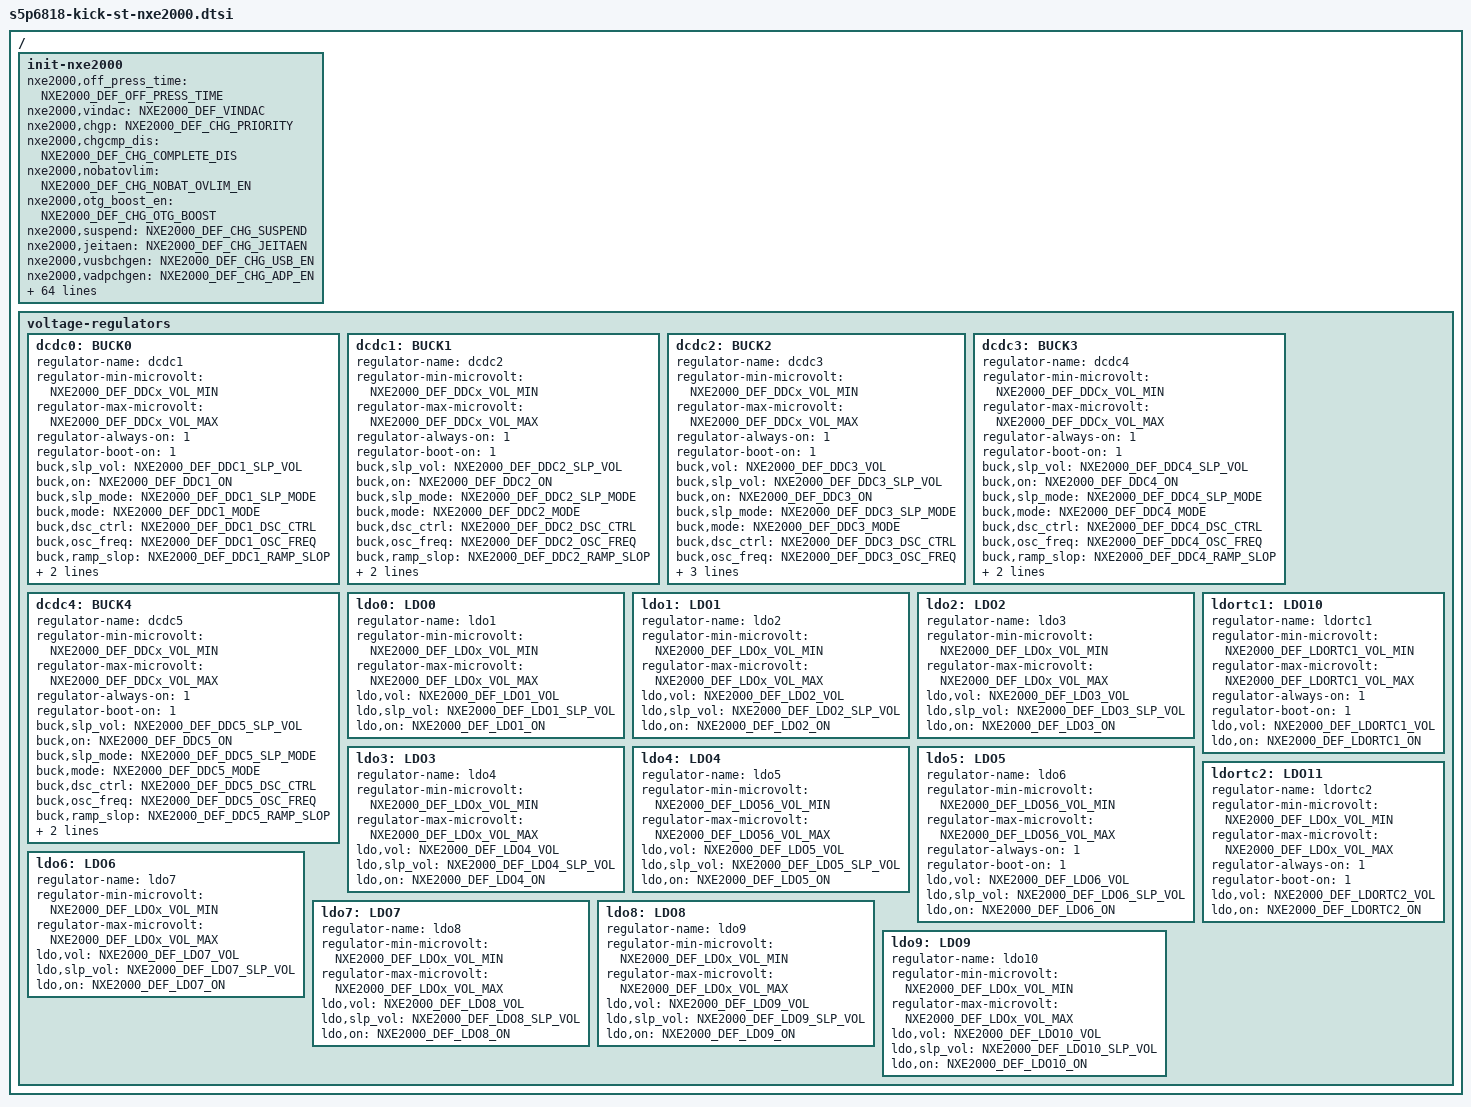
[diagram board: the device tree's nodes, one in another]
/*
 * (C) Copyright 2017 Nexell
 * Jongshin, Park <pjsin865@nexell.co.kr>
 *
 * SPDX-License-Identifier:      GPL-2.0+
 */

/*
 *	Config Value
 */

/* Off Press time Value = 0:0, 1:1, 2:2, 3:4, 4:6, 5:8, 6:10, 7:12 sec */
#define	NXE2000_DEF_OFF_PRESS_TIME 5

/* VINDAC Value = 0:2.6, 1:2.7, 2:2.8, 3:2.9, OTP = 2 */
#define	NXE2000_DEF_VINDAC 0

/* Limit Current Value(uA) */
#define NXE2000_DEF_LIMIT_ADP_AMP 2500000 /* MAX = 2.5A */
#define NXE2000_DEF_LIMIT_USB_AMP 1500000 /* MAX = 1.5A */
#define NXE2000_DEF_LIMIT_USBDATA_AMP 500000 /* MAX = 1.5A */

/* Charge Current Value(uA) */
#define NXE2000_DEF_CHG_ADP_AMP 1500000 /* MAX = 1.8A */
#define NXE2000_DEF_CHG_USB_AMP 1500000 /* MAX = 1.8A */
#define CHARGER_CURRENT_COMPLETE 3 /* (n + 1) x 50mA */

/* Battery Votage Value(uV) */
#define	NXE2000_DEF_CUTOFF_VOL 3300000
#define	NXE2000_DEF_LOWBAT_BATTERY_VOL 3500000
#define	NXE2000_DEF_LOWBAT_USB_PC_VOL 3600000
#define	NXE2000_DEF_LOWBAT_USB_ADP_VOL 3660000
#define	NXE2000_DEF_LOWBAT_ADP_VOL 3660000

/* DCDC Enable Value = 0: Off, 1: On, OTP = On */
#define	NXE2000_DEF_DDC1_ON 1
#define	NXE2000_DEF_DDC2_ON 1
#define	NXE2000_DEF_DDC3_ON 1
#define	NXE2000_DEF_DDC4_ON 1
#define	NXE2000_DEF_DDC5_ON 1

/* DCDC Voltage Value(uV) = 0: 0.60 ~ 3.5V, Step 12.5 mV */
#define	NXE2000_DEF_DDC1_VOL 1250000 /* OTP = 1.3V */
#define	NXE2000_DEF_DDC2_VOL 1200000 /* OTP = 1.2V */
#define	NXE2000_DEF_DDC3_VOL 3300000 /* OTP = 3.3V */
#define	NXE2000_DEF_DDC4_VOL 1500000 /* OTP = 1.5V */
#define	NXE2000_DEF_DDC5_VOL 1500000 /* OTP = 1.5V */

/* DCDC Sleep Voltage Value(uV) = 0: 0.60 ~ 3.5V, Step 12.5 mV */
#define	NXE2000_DEF_DDC1_SLP_VOL 1250000 /* OTP = 1.3V */
#define	NXE2000_DEF_DDC2_SLP_VOL 1200000 /* OTP = 1.2V */
#define	NXE2000_DEF_DDC3_SLP_VOL 3300000 /* OTP = 3.3V */
#define	NXE2000_DEF_DDC4_SLP_VOL 1500000 /* OTP = 1.5V */
#define	NXE2000_DEF_DDC5_SLP_VOL 1500000 /* OTP = 1.5V */

/* LDO Enable Value = 0: Off, 1: On */
#define	NXE2000_DEF_LDO1_ON 0
#define	NXE2000_DEF_LDO2_ON 0
#define	NXE2000_DEF_LDO3_ON 1
#define	NXE2000_DEF_LDO4_ON 0
#define	NXE2000_DEF_LDO5_ON 1
#define	NXE2000_DEF_LDO6_ON 1
#define	NXE2000_DEF_LDO7_ON 1
#define	NXE2000_DEF_LDO8_ON 0
#define	NXE2000_DEF_LDO9_ON 0
#define	NXE2000_DEF_LDO10_ON 1
#define	NXE2000_DEF_LDORTC1_ON 1
#define	NXE2000_DEF_LDORTC2_ON 1

/* LDO1~4 Voltage Value(uV) = 0: 0.90 ~ 3.5V, Step = 25mV */
/* LDO5~6 Voltage Value(uV) = 0: 0.60 ~ 3.5V, Step = 25mV */
/* LDO7~10 Voltage Value(uV) = 0: 0.90 ~ 3.5V, Step = 25mV */
#define	NXE2000_DEF_LDO1_VOL 2800000 /* OTP = 3.30V */
#define	NXE2000_DEF_LDO2_VOL 1800000 /* OTP = 1.80V */
#define	NXE2000_DEF_LDO3_VOL 1800000 /* OTP = 1.80V */
#define	NXE2000_DEF_LDO4_VOL 1800000 /* OTP = 1.80V */
#define	NXE2000_DEF_LDO5_VOL 1200000 /* OTP = 2.80V */
#define	NXE2000_DEF_LDO6_VOL 3300000 /* OTP = 3.30V */
#define	NXE2000_DEF_LDO7_VOL 2800000 /* OTP = 2.80V */
#define	NXE2000_DEF_LDO8_VOL 3300000 /* OTP = 3.30V */
#define	NXE2000_DEF_LDO9_VOL 3300000 /* OTP = 3.30V */
#define	NXE2000_DEF_LDO10_VOL 1000000 /* OTP = 1.20V */
#define	NXE2000_DEF_LDORTC1_VOL 1800000 /* OTP = 1.80V */
#define	NXE2000_DEF_LDORTC2_VOL 1000000 /* OTP = 1.00V */

/* LDO1~4 Sleep Voltage Value(uV) = 0: 0.90 ~ 3.5V, Step = 25mV */
/* LDO5~6 Sleep Voltage Value(uV) = 0: 0.60 ~ 3.5V, Step = 25mV */
/* LDO7~10 Sleep Voltage Value(uV) = 0: 0.90 ~ 3.5V, Step = 25mV */
#define	NXE2000_DEF_LDO1_SLP_VOL 2800000 /* OTP = 3.30V */
#define	NXE2000_DEF_LDO2_SLP_VOL 1800000 /* OTP = 1.80V */
#define	NXE2000_DEF_LDO3_SLP_VOL 1800000 /* OTP = 1.80V */
#define	NXE2000_DEF_LDO4_SLP_VOL 1800000 /* OTP = 1.80V */
#define	NXE2000_DEF_LDO5_SLP_VOL 1200000 /* OTP = 2.80V */
#define	NXE2000_DEF_LDO6_SLP_VOL 3300000 /* OTP = 3.30V */
#define	NXE2000_DEF_LDO7_SLP_VOL 2800000 /* OTP = 2.80V */
#define	NXE2000_DEF_LDO8_SLP_VOL 3300000 /* OTP = 3.30V */
#define	NXE2000_DEF_LDO9_SLP_VOL 3300000 /* OTP = 3.30V */
#define	NXE2000_DEF_LDO10_SLP_VOL 1000000 /* OTP = 1.20V */

/* DCDC and LDO Min/Max/Step Value */
#define	NXE2000_DEF_DDCx_VOL_STEP 12500
#define	NXE2000_DEF_LDOx_VOL_STEP 25000
#define	NXE2000_DEF_DDCx_VOL_MIN 600000
#define	NXE2000_DEF_DDCx_VOL_MAX 3500000
#define	NXE2000_DEF_LDOx_VOL_MIN 900000
#define	NXE2000_DEF_LDOx_VOL_MAX 3500000
#define	NXE2000_DEF_LDO56_VOL_MIN 600000
#define	NXE2000_DEF_LDO56_VOL_MAX 3500000
#define	NXE2000_DEF_LDORTC1_VOL_MIN 1700000
#define	NXE2000_DEF_LDORTC1_VOL_MAX 3500000

/* DCDC Mode Value = 0:AUTO(OTP), 1:PWM, 2:PSM, 3:AUTO */
#define	NXE2000_DEF_DDC1_MODE 0
#define	NXE2000_DEF_DDC2_MODE 0
#define	NXE2000_DEF_DDC3_MODE 0
#define	NXE2000_DEF_DDC4_MODE 0
#define	NXE2000_DEF_DDC5_MODE 0

/* DCDC Sleep Mode Value = 0:AUTO(OTP), 1:PWM, 2:PSM, 3:AUTO */
#define	NXE2000_DEF_DDC1_SLP_MODE 0
#define	NXE2000_DEF_DDC2_SLP_MODE 0
#define	NXE2000_DEF_DDC3_SLP_MODE 0
#define	NXE2000_DEF_DDC4_SLP_MODE 0
#define	NXE2000_DEF_DDC5_SLP_MODE 0

/* DCDC DSC Control Value = 0: Off, 1: On(OTP) */
#define	NXE2000_DEF_DDC1_DSC_CTRL 1
#define	NXE2000_DEF_DDC2_DSC_CTRL 1
#define	NXE2000_DEF_DDC3_DSC_CTRL 1
#define	NXE2000_DEF_DDC4_DSC_CTRL 1
#define	NXE2000_DEF_DDC5_DSC_CTRL 1

/* DCDC OSC FREQ Value(MHz) = 0: 1.5, 1: x, 2: 3.0, 3: x, OTP = 1.5MHz */
#define	NXE2000_DEF_DDC1_OSC_FREQ 0
#define	NXE2000_DEF_DDC2_OSC_FREQ 0
#define	NXE2000_DEF_DDC3_OSC_FREQ 0
#define	NXE2000_DEF_DDC4_OSC_FREQ 0
#define	NXE2000_DEF_DDC5_OSC_FREQ 0

/* DCDC RAMP SLOP Value(mV/us) = 0: 14, 1: 7, 2: 3.5, 3: x, OTP = 14mV/us */
#define	NXE2000_DEF_DDC1_RAMP_SLOP 0
#define	NXE2000_DEF_DDC2_RAMP_SLOP 0
#define	NXE2000_DEF_DDC3_RAMP_SLOP 0
#define	NXE2000_DEF_DDC4_RAMP_SLOP 0
#define	NXE2000_DEF_DDC5_RAMP_SLOP 0

/* DCDC CUR LIMIT Value(A) = 0: Nolimit, 1:3.2A, 2:3.7A, 3:4.0A, OTP = 3.2A */
#define	NXE2000_DEF_DDC1_CUR_LIMIT 3
#define	NXE2000_DEF_DDC2_CUR_LIMIT 3
#define	NXE2000_DEF_DDC3_CUR_LIMIT 1
#define	NXE2000_DEF_DDC4_CUR_LIMIT 1
#define	NXE2000_DEF_DDC5_CUR_LIMIT 1

/* DCDC LIMSHUT Enable Value = 0: Disable, 1: Enable */
#define	NXE2000_DEF_DDC1_LIMSHUT_EN 0
#define	NXE2000_DEF_DDC2_LIMSHUT_EN 0
#define	NXE2000_DEF_DDC3_LIMSHUT_EN 1
#define	NXE2000_DEF_DDC4_LIMSHUT_EN 1
#define	NXE2000_DEF_DDC5_LIMSHUT_EN 1

/* ADC Enable Value = 0: Disable, 1: Enable, default = Disable */
#define	NXE2000_DEF_ADC_AIN0 0
#define	NXE2000_DEF_ADC_AIN1 0
#define	NXE2000_DEF_ADC_VTHM 0
#define	NXE2000_DEF_ADC_VSYS 1
#define	NXE2000_DEF_ADC_VUSB 0
#define	NXE2000_DEF_ADC_VADP 0
#define	NXE2000_DEF_ADC_VBAT 1
#define	NXE2000_DEF_ADC_ILIM 0

/* ADC VAL = 0: Stop, 1:Single-mode, 2:Auto-mode, 3:Prohibit, OTP = Stop */
#define	NXE2000_DEF_ADCCNT3_ADRQ 2
/* ADC VAL = 0: one-time, 1: average of four-time, default = one-time */
#define	NXE2000_DEF_ADCCNT3_AVE 1
/* Select input of ADC in single-mode A/D conbersion */
#define	NXE2000_DEF_ADCCNT3_ADSEL 0

#define NXE2000_DEF_CHG_PRIORITY 0
#define NXE2000_DEF_CHG_COMPLETE_DIS 0
#define NXE2000_DEF_CHG_NOBAT_OVLIM_EN 1
#define NXE2000_DEF_CHG_OTG_BOOST 0
#define NXE2000_DEF_CHG_SUSPEND 0
#define NXE2000_DEF_CHG_JEITAEN 0
#define NXE2000_DEF_CHG_USB_EN 1
#define NXE2000_DEF_CHG_ADP_EN 1

/* VAL = 0: Off, 1: On, OTP = Off */
#define NXE2000_DEF_CHG_USB_VCONTMASK 0
#define NXE2000_DEF_CHG_ADP_VCONTMASK 0

/* VAL(V) = 0:4.1~4.2, 1:4.2~4.3, 2:4.3~4.4, 3:4.4~4.5, OTP=4.1~4.2V */
#define NXE2000_DEF_CHG_VUSB_BUCK_THS 0
#define NXE2000_DEF_CHG_VADP_BUCK_THS 0

/* VAL(V) = 0:3.60, 1:4.00, 2:4.40, 3:4.55, default=4.00V */
#define NXE2000_DEF_CHG_VSYS_VOL 3
/* VAL(V) = 0:4.8~5.3, 1:5.0~5.5, 2:5.2~5.7, 3:5.2~5.7, default=5.0~5.5V */
#define NXE2000_DEF_CHG_VSYS_OVER_VOL 1

#define NXE2000_DEF_CHG_RAPID_TTIM_40 0
#define NXE2000_DEF_CHG_RAPID_TTIM_80 1
#define NXE2000_DEF_CHG_RAPID_TTIMDIS 2
/* VAL(sec) = 0: 0.1, 1: 0.5, 2: 1 3: 5, default = 1sec */
#define NXE2000_DEF_CHG_RAPID_CTIME 2
/* VAL(min) = 0: 120, 1: 180, 2: 240 3: 300, default = 300min */
#define NXE2000_DEF_CHG_RAPID_RTIME 3

/* VAL(V) = 0:2.7~2.8, 1:2.8~2.9, 2:2.9~3.0, 3:3.0~3.1, 4:3.1~3.2,
                  5: 3.2~3.3, 6:3.3~3.4, 7:3.4~3.5, OTP=3.4~3.5V */
#define NXE2000_DEF_CHG_POWER_ON_VOL 4
/* VAL(V) = 0:3.95~4.38, 1:4.10~4.53, default=3.95~4.38V */
#define NXE2000_DEF_CHG_VBATOV_SET 0
/* VAL(V) = 0:3.0~3.1, 1:3.1~3.2, 2:3.2~3.3, 3:3.3~3.4, OTP=3.3~3.4V */
#define NXE2000_DEF_CHG_VWEAK 1
/* VAL(V) = 0: 2.9 ~ 3.0, 1: 2.8 ~ 2.9, OTP = 2.9 ~ 3.0V */
#define NXE2000_DEF_CHG_VDEAD 0
/* VAL(V) = 0: 2.7 ~ 2.8, 1: 2.5 ~ 2.6, OTP = 2.7 ~ 2.8V */
#define NXE2000_DEF_CHG_VSHORT 1
/* VAL(V) = 0: 4.05, 1: 4.10, 2: 4.15, 3: 4.20,  4 ~ 7: 4.35, default = 4.10V */
#define NXE2000_DEF_CHG_VFCHG 3
/* VAL(V) = 0: 3.85, 1: 3.90, 2: 3.95, 3: 4.00,  4 ~ 7: 4.10  default = 3.90V */
#define NXE2000_DEF_CHG_VRCHG 3

/* DIE TEMP Value('C)= 0: 80, 1: 100, OTP = 80 */
#define NXE2000_DEF_DIE_RETURN_TEMP 0
/* DIE TEMP Value('C)= 0: 100, 1: 120 */
#define NXE2000_DEF_DIE_ERROR_TEMP 0
/* DIE TEMP Value('C)= 0: 100, 1: 120, 2: 135, 3: 135, OTP = 120  */
#define NXE2000_DEF_DIE_SHUTDOWN_TEMP 3

/* REPCNT */
#define	NXE2000_DEF_REPCNT_REPWRON 0
#define	NXE2000_DEF_REPCNT_REPWRTIM 0
#define	NXE2000_DEF_REPCNT_OFF_RESETO 0

/* WATCHDOG */
#define	NXE2000_DEF_WDOG_TIM 3
#define	NXE2000_DEF_WDOG_EN 0
#define	NXE2000_DEF_WDOG_SLPEN 0

/* PWRIREN */
#define	NXE2000_DEF_PWRIREN_WDOG 0
#define	NXE2000_DEF_PWRIREN_NOE_OFF 0
#define	NXE2000_DEF_PWRIREN_PWRON_OFF 0
#define	NXE2000_DEF_PWRIREN_PREOT 0
#define	NXE2000_DEF_PWRIREN_PRVINDT 0
#define	NXE2000_DEF_PWRIREN_EXTIN 0
#define	NXE2000_DEF_PWRIREN_PWRON 0

/ {
	init-nxe2000 {
		nxe2000,off_press_time = <NXE2000_DEF_OFF_PRESS_TIME>;

		nxe2000,vindac = <NXE2000_DEF_VINDAC>;

		nxe2000,chgp = <NXE2000_DEF_CHG_PRIORITY>;
		nxe2000,chgcmp_dis = <NXE2000_DEF_CHG_COMPLETE_DIS>;
		nxe2000,nobatovlim = <NXE2000_DEF_CHG_NOBAT_OVLIM_EN>;
		nxe2000,otg_boost_en = <NXE2000_DEF_CHG_OTG_BOOST>;
		nxe2000,suspend = <NXE2000_DEF_CHG_SUSPEND>;
		nxe2000,jeitaen = <NXE2000_DEF_CHG_JEITAEN>;
		nxe2000,vusbchgen = <NXE2000_DEF_CHG_USB_EN>;
		nxe2000,vadpchgen = <NXE2000_DEF_CHG_ADP_EN>;

		nxe2000,chg_usb_vcontmask = <NXE2000_DEF_CHG_USB_VCONTMASK>;
		nxe2000,chg_adp_vcontmask = <NXE2000_DEF_CHG_ADP_VCONTMASK>;
		nxe2000,chg_vbus_buck_ths = <NXE2000_DEF_CHG_VUSB_BUCK_THS>;
		nxe2000,chg_vadp_buck_ths = <NXE2000_DEF_CHG_VADP_BUCK_THS>;

		nxe2000,vsys_vol = <NXE2000_DEF_CHG_VSYS_VOL>;
		nxe2000,vsys_over_vol = <NXE2000_DEF_CHG_VSYS_OVER_VOL>;

		nxe2000,rapid_ttime = <NXE2000_DEF_CHG_RAPID_TTIM_80>;
		nxe2000,rapid_ctime = <NXE2000_DEF_CHG_RAPID_CTIME>;
		nxe2000,rapid_rtime = <NXE2000_DEF_CHG_RAPID_RTIME>;

		nxe2000,pwr_on_vol = <NXE2000_DEF_CHG_POWER_ON_VOL>;
		nxe2000,vbatov_set = <NXE2000_DEF_CHG_VBATOV_SET>;
		nxe2000,vweak = <NXE2000_DEF_CHG_VWEAK>;
		nxe2000,vdead = <NXE2000_DEF_CHG_VDEAD>;
		nxe2000,vshort = <NXE2000_DEF_CHG_VSHORT>;

		nxe2000,vfchg = <NXE2000_DEF_CHG_VFCHG>;

		nxe2000,die_return_temp = <NXE2000_DEF_DIE_RETURN_TEMP>;
		nxe2000,die_error_temp = <NXE2000_DEF_DIE_ERROR_TEMP>;
		nxe2000,die_shutdown_temp = <NXE2000_DEF_DIE_SHUTDOWN_TEMP>;

		nxe2000,repcnt_off_reseto = <NXE2000_DEF_REPCNT_OFF_RESETO>;
		nxe2000,repcnt_repwrtim = <NXE2000_DEF_REPCNT_REPWRTIM>;
		nxe2000,repcnt_repwron = <NXE2000_DEF_REPCNT_REPWRON>;

		nxe2000,wdog_slpen = <NXE2000_DEF_WDOG_SLPEN>;
		nxe2000,wdog_en = <NXE2000_DEF_WDOG_EN>;
		nxe2000,wdog_tim = <NXE2000_DEF_WDOG_TIM>;

		nxe2000,pwrien_wdog = <NXE2000_DEF_PWRIREN_WDOG>;
		nxe2000,pwrien_noe_off = <NXE2000_DEF_PWRIREN_NOE_OFF>;
		nxe2000,pwrien_pwron_off = <NXE2000_DEF_PWRIREN_PWRON_OFF>;
		nxe2000,pwrien_preot = <NXE2000_DEF_PWRIREN_PREOT>;
		nxe2000,pwrien_prvindt = <NXE2000_DEF_PWRIREN_PRVINDT>;
		nxe2000,pwrien_extin = <NXE2000_DEF_PWRIREN_EXTIN>;
		nxe2000,pwrien_pwron = <NXE2000_DEF_PWRIREN_PWRON>;

		nxe2000,adc_ain0 = <NXE2000_DEF_ADC_AIN0>;
		nxe2000,adc_ain1 = <NXE2000_DEF_ADC_AIN1>;
		nxe2000,adc_vthm = <NXE2000_DEF_ADC_VTHM>;
		nxe2000,adc_vsys = <NXE2000_DEF_ADC_VSYS>;
		nxe2000,adc_vusb = <NXE2000_DEF_ADC_VUSB>;
		nxe2000,adc_vadp = <NXE2000_DEF_ADC_VADP>;
		nxe2000,adc_vbat = <NXE2000_DEF_ADC_VBAT>;
		nxe2000,adc_ilim = <NXE2000_DEF_ADC_ILIM>;

		nxe2000,adccnt3_adrq = <NXE2000_DEF_ADCCNT3_ADRQ>;
		nxe2000,adccnt3_ave = <NXE2000_DEF_ADCCNT3_AVE>;
		nxe2000,adccnt3_adsel = <NXE2000_DEF_ADCCNT3_ADSEL>;
	}; /* init-nxe2000 */

	voltage-regulators {
		dcdc0: BUCK0 {
			regulator-name = "dcdc1";
			regulator-min-microvolt = <NXE2000_DEF_DDCx_VOL_MIN>;
			regulator-max-microvolt = <NXE2000_DEF_DDCx_VOL_MAX>;
			regulator-always-on = <1>;
			regulator-boot-on = <1>;

			/* buck,vol = <NXE2000_DEF_DDC1_VOL>; */
			buck,slp_vol = <NXE2000_DEF_DDC1_SLP_VOL>;
			buck,on = <NXE2000_DEF_DDC1_ON>;

			buck,slp_mode = <NXE2000_DEF_DDC1_SLP_MODE>;
			buck,mode = <NXE2000_DEF_DDC1_MODE>;
			buck,dsc_ctrl = <NXE2000_DEF_DDC1_DSC_CTRL>;

			buck,osc_freq = <NXE2000_DEF_DDC1_OSC_FREQ>;
			buck,ramp_slop = <NXE2000_DEF_DDC1_RAMP_SLOP>;
			buck,cur_limit = <NXE2000_DEF_DDC1_CUR_LIMIT>;
			buck,limshut_en = <NXE2000_DEF_DDC1_LIMSHUT_EN>;
		};

		dcdc1: BUCK1 {
			regulator-name = "dcdc2";
			regulator-min-microvolt = <NXE2000_DEF_DDCx_VOL_MIN>;
			regulator-max-microvolt = <NXE2000_DEF_DDCx_VOL_MAX>;
			regulator-always-on = <1>;
			regulator-boot-on = <1>;

			/* buck,vol = <NXE2000_DEF_DDC2_VOL>; */
			buck,slp_vol = <NXE2000_DEF_DDC2_SLP_VOL>;
			buck,on = <NXE2000_DEF_DDC2_ON>;

			buck,slp_mode = <NXE2000_DEF_DDC2_SLP_MODE>;
			buck,mode = <NXE2000_DEF_DDC2_MODE>;
			buck,dsc_ctrl = <NXE2000_DEF_DDC2_DSC_CTRL>;

			buck,osc_freq = <NXE2000_DEF_DDC2_OSC_FREQ>;
			buck,ramp_slop = <NXE2000_DEF_DDC2_RAMP_SLOP>;
			buck,cur_limit = <NXE2000_DEF_DDC2_CUR_LIMIT>;
			buck,limshut_en = <NXE2000_DEF_DDC2_LIMSHUT_EN>;
		};

		dcdc2: BUCK2 {
			regulator-name = "dcdc3";
			regulator-min-microvolt = <NXE2000_DEF_DDCx_VOL_MIN>;
			regulator-max-microvolt = <NXE2000_DEF_DDCx_VOL_MAX>;
			regulator-always-on = <1>;
			regulator-boot-on = <1>;

			buck,vol = <NXE2000_DEF_DDC3_VOL>;
			buck,slp_vol = <NXE2000_DEF_DDC3_SLP_VOL>;
			buck,on = <NXE2000_DEF_DDC3_ON>;

			buck,slp_mode = <NXE2000_DEF_DDC3_SLP_MODE>;
			buck,mode = <NXE2000_DEF_DDC3_MODE>;
			buck,dsc_ctrl = <NXE2000_DEF_DDC3_DSC_CTRL>;

			buck,osc_freq = <NXE2000_DEF_DDC3_OSC_FREQ>;
			buck,ramp_slop = <NXE2000_DEF_DDC3_RAMP_SLOP>;
			buck,cur_limit = <NXE2000_DEF_DDC3_CUR_LIMIT>;
			buck,limshut_en = <NXE2000_DEF_DDC3_LIMSHUT_EN>;
		};

		dcdc3: BUCK3 {
			regulator-name = "dcdc4";
			regulator-min-microvolt = <NXE2000_DEF_DDCx_VOL_MIN>;
			regulator-max-microvolt = <NXE2000_DEF_DDCx_VOL_MAX>;
			regulator-always-on = <1>;
			regulator-boot-on = <1>;

			/* buck,vol = <NXE2000_DEF_DDC4_VOL>; */
			buck,slp_vol = <NXE2000_DEF_DDC4_SLP_VOL>;
			buck,on = <NXE2000_DEF_DDC4_ON>;

			buck,slp_mode = <NXE2000_DEF_DDC4_SLP_MODE>;
			buck,mode = <NXE2000_DEF_DDC4_MODE>;
			buck,dsc_ctrl = <NXE2000_DEF_DDC4_DSC_CTRL>;

			buck,osc_freq = <NXE2000_DEF_DDC4_OSC_FREQ>;
			buck,ramp_slop = <NXE2000_DEF_DDC4_RAMP_SLOP>;
			buck,cur_limit = <NXE2000_DEF_DDC4_CUR_LIMIT>;
			buck,limshut_en = <NXE2000_DEF_DDC4_LIMSHUT_EN>;
		};

		dcdc4: BUCK4 {
			regulator-name = "dcdc5";
			regulator-min-microvolt = <NXE2000_DEF_DDCx_VOL_MIN>;
			regulator-max-microvolt = <NXE2000_DEF_DDCx_VOL_MAX>;
			regulator-always-on = <1>;
			regulator-boot-on = <1>;

			/* buck,vol = <NXE2000_DEF_DDC5_VOL>; */
			buck,slp_vol = <NXE2000_DEF_DDC5_SLP_VOL>;
			buck,on = <NXE2000_DEF_DDC5_ON>;

			buck,slp_mode = <NXE2000_DEF_DDC5_SLP_MODE>;
			buck,mode = <NXE2000_DEF_DDC5_MODE>;
			buck,dsc_ctrl = <NXE2000_DEF_DDC5_DSC_CTRL>;

			buck,osc_freq = <NXE2000_DEF_DDC5_OSC_FREQ>;
			buck,ramp_slop = <NXE2000_DEF_DDC5_RAMP_SLOP>;
			buck,cur_limit = <NXE2000_DEF_DDC5_CUR_LIMIT>;
			buck,limshut_en = <NXE2000_DEF_DDC5_LIMSHUT_EN>;
		};

		ldo0: LDO0 {
			regulator-name = "ldo1";
			regulator-min-microvolt = <NXE2000_DEF_LDOx_VOL_MIN>;
			regulator-max-microvolt = <NXE2000_DEF_LDOx_VOL_MAX>;

			ldo,vol = <NXE2000_DEF_LDO1_VOL>;
			ldo,slp_vol = <NXE2000_DEF_LDO1_SLP_VOL>;
			ldo,on = <NXE2000_DEF_LDO1_ON>;
		};

		ldo1: LDO1 {
			regulator-name = "ldo2";
			regulator-min-microvolt = <NXE2000_DEF_LDOx_VOL_MIN>;
			regulator-max-microvolt = <NXE2000_DEF_LDOx_VOL_MAX>;
			ldo,vol = <NXE2000_DEF_LDO2_VOL>;
			ldo,slp_vol = <NXE2000_DEF_LDO2_SLP_VOL>;
			ldo,on = <NXE2000_DEF_LDO2_ON>;
		};

		ldo2: LDO2 {
			regulator-name = "ldo3";
			regulator-min-microvolt = <NXE2000_DEF_LDOx_VOL_MIN>;
			regulator-max-microvolt = <NXE2000_DEF_LDOx_VOL_MAX>;

			ldo,vol = <NXE2000_DEF_LDO3_VOL>;
			ldo,slp_vol = <NXE2000_DEF_LDO3_SLP_VOL>;
			ldo,on = <NXE2000_DEF_LDO3_ON>;
		};

		ldo3: LDO3 {
			regulator-name = "ldo4";
			regulator-min-microvolt = <NXE2000_DEF_LDOx_VOL_MIN>;
			regulator-max-microvolt = <NXE2000_DEF_LDOx_VOL_MAX>;

			ldo,vol = <NXE2000_DEF_LDO4_VOL>;
			ldo,slp_vol = <NXE2000_DEF_LDO4_SLP_VOL>;
			ldo,on = <NXE2000_DEF_LDO4_ON>;
		};

		ldo4: LDO4 {
			regulator-name = "ldo5";
			regulator-min-microvolt = <NXE2000_DEF_LDO56_VOL_MIN>;
			regulator-max-microvolt = <NXE2000_DEF_LDO56_VOL_MAX>;

			ldo,vol = <NXE2000_DEF_LDO5_VOL>;
			ldo,slp_vol = <NXE2000_DEF_LDO5_SLP_VOL>;
			ldo,on = <NXE2000_DEF_LDO5_ON>;
		};

		ldo5: LDO5 {
			regulator-name = "ldo6";
			regulator-min-microvolt = <NXE2000_DEF_LDO56_VOL_MIN>;
			regulator-max-microvolt = <NXE2000_DEF_LDO56_VOL_MAX>;
			regulator-always-on = <1>;
			regulator-boot-on = <1>;

			ldo,vol = <NXE2000_DEF_LDO6_VOL>;
			ldo,slp_vol = <NXE2000_DEF_LDO6_SLP_VOL>;
			ldo,on = <NXE2000_DEF_LDO6_ON>;
		};

		ldo6: LDO6 {
			regulator-name = "ldo7";
			regulator-min-microvolt = <NXE2000_DEF_LDOx_VOL_MIN>;
			regulator-max-microvolt = <NXE2000_DEF_LDOx_VOL_MAX>;

			ldo,vol = <NXE2000_DEF_LDO7_VOL>;
			ldo,slp_vol = <NXE2000_DEF_LDO7_SLP_VOL>;
			ldo,on = <NXE2000_DEF_LDO7_ON>;
		};

		ldo7: LDO7 {
			regulator-name = "ldo8";
			regulator-min-microvolt = <NXE2000_DEF_LDOx_VOL_MIN>;
			regulator-max-microvolt = <NXE2000_DEF_LDOx_VOL_MAX>;

			ldo,vol = <NXE2000_DEF_LDO8_VOL>;
			ldo,slp_vol = <NXE2000_DEF_LDO8_SLP_VOL>;
			ldo,on = <NXE2000_DEF_LDO8_ON>;
		};

		ldo8: LDO8 {
			regulator-name = "ldo9";
			regulator-min-microvolt = <NXE2000_DEF_LDOx_VOL_MIN>;
			regulator-max-microvolt = <NXE2000_DEF_LDOx_VOL_MAX>;

			ldo,vol = <NXE2000_DEF_LDO9_VOL>;
			ldo,slp_vol = <NXE2000_DEF_LDO9_SLP_VOL>;
			ldo,on = <NXE2000_DEF_LDO9_ON>;
		};

		ldo9: LDO9 {
			regulator-name = "ldo10";
			regulator-min-microvolt = <NXE2000_DEF_LDOx_VOL_MIN>;
			regulator-max-microvolt = <NXE2000_DEF_LDOx_VOL_MAX>;

			ldo,vol = <NXE2000_DEF_LDO10_VOL>;
			ldo,slp_vol = <NXE2000_DEF_LDO10_SLP_VOL>;
			ldo,on = <NXE2000_DEF_LDO10_ON>;
		};

		ldortc1: LDO10 {
			regulator-name = "ldortc1";
			regulator-min-microvolt = <NXE2000_DEF_LDORTC1_VOL_MIN>;
			regulator-max-microvolt = <NXE2000_DEF_LDORTC1_VOL_MAX>;
			regulator-always-on = <1>;
			regulator-boot-on = <1>;

			ldo,vol = <NXE2000_DEF_LDORTC1_VOL>;
			ldo,on = <NXE2000_DEF_LDORTC1_ON>;
		};

		ldortc2: LDO11 {
			regulator-name = "ldortc2";
			regulator-min-microvolt = <NXE2000_DEF_LDOx_VOL_MIN>;
			regulator-max-microvolt = <NXE2000_DEF_LDOx_VOL_MAX>;
			regulator-always-on = <1>;
			regulator-boot-on = <1>;

			ldo,vol = <NXE2000_DEF_LDORTC2_VOL>;
			ldo,on = <NXE2000_DEF_LDORTC2_ON>;
		};
	}; /* voltage-regulators */
};
